AUTOSAR XML (schema 314)
package /ComponentType
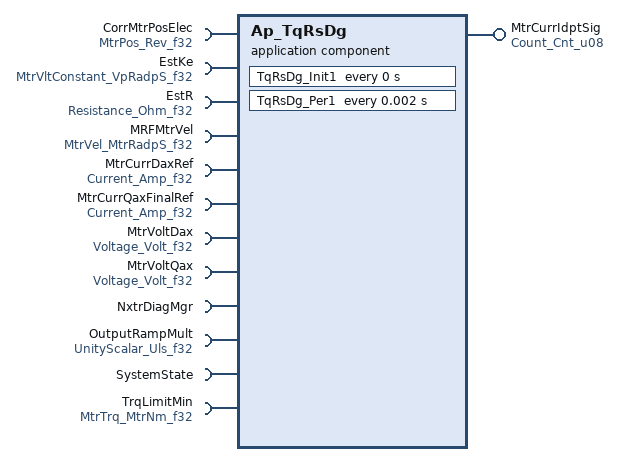
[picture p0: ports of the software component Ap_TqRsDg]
  application software component type Ap_TqRsDg
    provide port MtrCurrIdptSig: unqueued-sender-com-spec{data-element=Cnt_u08, can-invalidate=false, init-value=D_TWO_CNT_U08}, provided-interface=Count_Cnt_u08
    12 x require port:
      CorrMtrPosElec: unqueued-receiver-com-spec{data-element=Rev_f32, init-value=D_ZERO_ULS_F32}, required-interface=MtrPos_Rev_f32
      EstKe: unqueued-receiver-com-spec{data-element=VpRadpS_f32, init-value=D_ZERO_ULS_F32}, required-interface=MtrVltConstant_VpRadpS_f32
      EstR: unqueued-receiver-com-spec{data-element=Ohm_f32, init-value=D_ZERO_ULS_F32}, required-interface=Resistance_Ohm_f32
      MRFMtrVel: unqueued-receiver-com-spec{data-element=MtrRadpS_f32, init-value=D_ZERO_ULS_F32}, required-interface=MtrVel_MtrRadpS_f32
      MtrCurrDaxRef: unqueued-receiver-com-spec{data-element=Amp_f32, init-value=D_ZERO_ULS_F32}, required-interface=Current_Amp_f32
      MtrCurrQaxFinalRef: unqueued-receiver-com-spec{data-element=Amp_f32, init-value=D_ZERO_ULS_F32}, required-interface=Current_Amp_f32
      MtrVoltDax: unqueued-receiver-com-spec{data-element=Volt_f32, init-value=D_ZERO_ULS_F32}, required-interface=Voltage_Volt_f32
      MtrVoltQax: unqueued-receiver-com-spec{data-element=Volt_f32, init-value=D_ZERO_ULS_F32}, required-interface=Voltage_Volt_f32
      NxtrDiagMgr: required-com-specs=[GetNTCActive, GetNTCFailed, GetNTCStatus, SetNTCStatus], required-interface=NxtrDiagMgr
      OutputRampMult: unqueued-receiver-com-spec{data-element=Uls_f32, init-value=D_ZERO_ULS_F32}, required-interface=UnityScalar_Uls_f32
      SystemState: required-interface=SystemState
      TrqLimitMin: unqueued-receiver-com-spec{data-element=MtrNm_f32, init-value=D_ZERO_ULS_F32}, required-interface=MtrTrq_MtrNm_f32
  internal behavior Ap_TqRsDg_InternalBehavior: component=Ap_TqRsDg
    timing event TqRsDg_Init1_InitEvent: start-on-event=TqRsDg_Init1, period=0
    timing event TMT_TqRsDg_Per1: mode-dependency=dependent-on-mode=[SystemState.Mode.DISABLE, SystemState.Mode.OFF, SystemState.Mode.WARMINIT], start-on-event=TqRsDg_Per1, period=0.002
    port-api-options:
      enable-take-address=false, indirect-api=false, port=CorrMtrPosElec
      enable-take-address=false, indirect-api=false, port=EstKe
      enable-take-address=false, indirect-api=false, port=EstR
      enable-take-address=false, indirect-api=false, port=MRFMtrVel
      enable-take-address=false, indirect-api=false, port=MtrCurrDaxRef
      enable-take-address=false, indirect-api=false, port=MtrCurrIdptSig
      enable-take-address=false, indirect-api=false, port=MtrCurrQaxFinalRef
      enable-take-address=false, indirect-api=false, port=MtrVoltDax
      enable-take-address=false, indirect-api=false, port=MtrVoltQax
      enable-take-address=false, indirect-api=false, port=NxtrDiagMgr
      enable-take-address=false, indirect-api=false, port=OutputRampMult
      enable-take-address=false, indirect-api=false, port=SystemState
      enable-take-address=false, indirect-api=false, port=TrqLimitMin
    runnable TqRsDg_Init1
    runnable TqRsDg_Per1
      10 x data read access:
        READ_CorrMtrPosElec_Rev_f32: data-element=CorrMtrPosElec.Rev_f32
        READ_EstKe_VpRadpS_f32: data-element=EstKe.VpRadpS_f32
        READ_EstR_Ohm_f32: data-element=EstR.Ohm_f32
        READ_MRFMtrVel_MtrRadpS_f32: data-element=MRFMtrVel.MtrRadpS_f32
        READ_MtrCurrDaxRef_Amp_f32: data-element=MtrCurrDaxRef.Amp_f32
        READ_MtrCurrQaxFinalRef_Amp_f32: data-element=MtrCurrQaxFinalRef.Amp_f32
        READ_MtrVoltDax_Volt_f32: data-element=MtrVoltDax.Volt_f32
        READ_MtrVoltQax_Volt_f32: data-element=MtrVoltQax.Volt_f32
        READ_OutputRampMult_Uls_f32: data-element=OutputRampMult.Uls_f32
        READ_TrqLimitMin_MtrNm_f32: data-element=TrqLimitMin.MtrNm_f32
      data write access WRITE_MtrCurrIdptSig_Cnt_u08: data-element=MtrCurrIdptSig.Cnt_u08
      sync call SC_NxtrDiagMgr_SetNTCStatus: operation=NxtrDiagMgr.SetNTCStatus, timeout=0
  swc implementation Ap_TqRsDg_Implementation: behavior=Ap_TqRsDg_InternalBehavior
    code-descriptors:
      code Code: type=SRC
